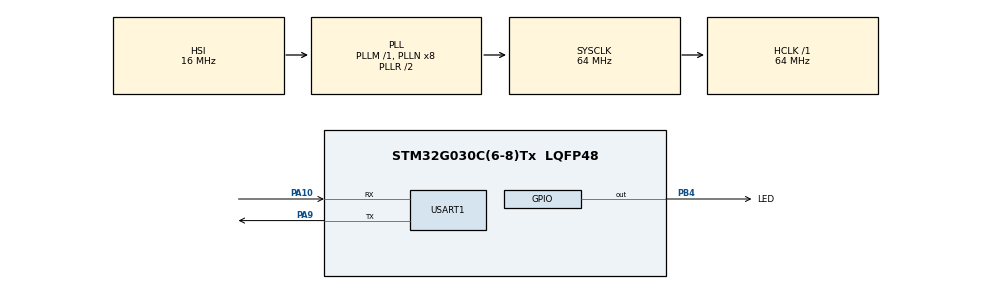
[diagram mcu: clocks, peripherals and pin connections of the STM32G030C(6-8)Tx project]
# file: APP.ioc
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Mcu.Family=STM32G0
Mcu.Name=STM32G030C(6-8)Tx
Mcu.Package=LQFP48
PA10.Mode=Asynchronous
PA10.Signal=USART1_RX
PA13.Mode=Serial_Wire
PA13.Signal=SYS_SWDIO
PA14-BOOT0.Mode=Serial_Wire
PA14-BOOT0.Signal=SYS_SWCLK
PA9.Mode=Asynchronous
PA9.Signal=USART1_TX
PB4.GPIO_Label=LED
PB4.Signal=GPIO_Output
ProjectManager.HeapSize=0x200
ProjectManager.StackSize=0x400
ProjectManager.TargetToolchain=MDK-ARM V5.32
RCC.ADCFreq_Value=64000000
RCC.AHBFreq_Value=64000000
RCC.CortexFreq_Value=64000000
RCC.EXTERNAL_CLOCK_VALUE=12288000
RCC.HCLKFreq_Value=64000000
RCC.HSE_VALUE=8000000
RCC.HSI_VALUE=16000000
RCC.LSE_VALUE=32768
RCC.SYSCLKFreq_VALUE=64000000
RCC.SYSCLKSource=RCC_SYSCLKSOURCE_PLLCLK
RCC.VCOOutputFreq_Value=128000000
USART1.VirtualMode-Asynchronous=VM_ASYNC
board=custom

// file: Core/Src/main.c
/* USER CODE BEGIN Header */
/**
  ******************************************************************************
  * @file           : main.c
  * @brief          : Main program body
  ******************************************************************************
  * @attention
  *
  * <h2><center>&copy; Copyright (c) 2021 STMicroelectronics.
  * All rights reserved.</center></h2>
  *
  * This software component is licensed by ST under BSD 3-Clause license,
  * the "License"; You may not use this file except in compliance with the
  * License. You may obtain a copy of the License at:
  *                        opensource.org/licenses/BSD-3-Clause
  *
  ******************************************************************************
  */
/* USER CODE END Header */
#include "main.h"

UART_HandleTypeDef huart1;

void SystemClock_Config(void);
static void MX_GPIO_Init(void);
static void MX_USART1_UART_Init(void);

int main(void)
{

  /* MCU Configuration--------------------------------------------------------*/

  /* Reset of all peripherals, Initializes the Flash interface and the Systick. */
  HAL_Init();

  /* Configure the system clock */
  SystemClock_Config();

  /* Initialize all configured peripherals */
  MX_GPIO_Init();
  MX_USART1_UART_Init();
  /* USER CODE BEGIN 2 */
    uint8_t buf[] = "\r\nSTM32G030 UART1(115200) APP V1.0\r\n";
    HAL_UART_Transmit(&huart1,buf,sizeof(buf)-1,100);
  /* USER CODE END 2 */

  /* Infinite loop */
  while (1)
  {

    /* USER CODE BEGIN 3 */
    HAL_Delay(500);
    HAL_GPIO_TogglePin(LED_GPIO_Port, LED_Pin);

  }
  /* USER CODE END 3 */
}

void SystemClock_Config(void)
{
  RCC_OscInitTypeDef RCC_OscInitStruct = {0};
  RCC_ClkInitTypeDef RCC_ClkInitStruct = {0};
  RCC_PeriphCLKInitTypeDef PeriphClkInit = {0};

  /** Configure the main internal regulator output voltage
  */
  HAL_PWREx_ControlVoltageScaling(PWR_REGULATOR_VOLTAGE_SCALE1);
  /** Initializes the RCC Oscillators according to the specified parameters
  * in the RCC_OscInitTypeDef structure.
  */
  RCC_OscInitStruct.OscillatorType = RCC_OSCILLATORTYPE_HSI;
  RCC_OscInitStruct.HSIState = RCC_HSI_ON;
  RCC_OscInitStruct.HSIDiv = RCC_HSI_DIV1;
  RCC_OscInitStruct.HSICalibrationValue = RCC_HSICALIBRATION_DEFAULT;
  RCC_OscInitStruct.PLL.PLLState = RCC_PLL_ON;
  RCC_OscInitStruct.PLL.PLLSource = RCC_PLLSOURCE_HSI;
  RCC_OscInitStruct.PLL.PLLM = RCC_PLLM_DIV1;
  RCC_OscInitStruct.PLL.PLLN = 8;
  RCC_OscInitStruct.PLL.PLLP = RCC_PLLP_DIV2;
  RCC_OscInitStruct.PLL.PLLR = RCC_PLLR_DIV2;
  if (HAL_RCC_OscConfig(&RCC_OscInitStruct) != HAL_OK)
  {
    Error_Handler();
  }
  /** Initializes the CPU, AHB and APB buses clocks
  */
  RCC_ClkInitStruct.ClockType = RCC_CLOCKTYPE_HCLK|RCC_CLOCKTYPE_SYSCLK
                              |RCC_CLOCKTYPE_PCLK1;
  RCC_ClkInitStruct.SYSCLKSource = RCC_SYSCLKSOURCE_PLLCLK;
  RCC_ClkInitStruct.AHBCLKDivider = RCC_SYSCLK_DIV1;
  RCC_ClkInitStruct.APB1CLKDivider = RCC_HCLK_DIV1;

  if (HAL_RCC_ClockConfig(&RCC_ClkInitStruct, FLASH_LATENCY_2) != HAL_OK)
  {
    Error_Handler();
  }
  /** Initializes the peripherals clocks
  */
  PeriphClkInit.PeriphClockSelection = RCC_PERIPHCLK_USART1;
  PeriphClkInit.Usart1ClockSelection = RCC_USART1CLKSOURCE_PCLK1;
  if (HAL_RCCEx_PeriphCLKConfig(&PeriphClkInit) != HAL_OK)
  {
    Error_Handler();
  }
}

static void MX_USART1_UART_Init(void)
{

  huart1.Instance = USART1;
  huart1.Init.BaudRate = 115200;
  huart1.Init.WordLength = UART_WORDLENGTH_8B;
  huart1.Init.StopBits = UART_STOPBITS_1;
  huart1.Init.Parity = UART_PARITY_NONE;
  huart1.Init.Mode = UART_MODE_TX_RX;
  huart1.Init.HwFlowCtl = UART_HWCONTROL_NONE;
  huart1.Init.OverSampling = UART_OVERSAMPLING_16;
  huart1.Init.OneBitSampling = UART_ONE_BIT_SAMPLE_DISABLE;
  huart1.Init.ClockPrescaler = UART_PRESCALER_DIV1;
  huart1.AdvancedInit.AdvFeatureInit = UART_ADVFEATURE_NO_INIT;
  if (HAL_UART_Init(&huart1) != HAL_OK)
  {
    Error_Handler();
  }
  if (HAL_UARTEx_SetTxFifoThreshold(&huart1, UART_TXFIFO_THRESHOLD_1_8) != HAL_OK)
  {
    Error_Handler();
  }
  if (HAL_UARTEx_SetRxFifoThreshold(&huart1, UART_RXFIFO_THRESHOLD_1_8) != HAL_OK)
  {
    Error_Handler();
  }
  if (HAL_UARTEx_DisableFifoMode(&huart1) != HAL_OK)
  {
    Error_Handler();
  }

}

static void MX_GPIO_Init(void)
{
  GPIO_InitTypeDef GPIO_InitStruct = {0};

  /* GPIO Ports Clock Enable */
  __HAL_RCC_GPIOA_CLK_ENABLE();
  __HAL_RCC_GPIOB_CLK_ENABLE();

  /*Configure GPIO pin Output Level */
  HAL_GPIO_WritePin(LED_GPIO_Port, LED_Pin, GPIO_PIN_RESET);

  /*Configure GPIO pin : LED_Pin */
  GPIO_InitStruct.Pin = LED_Pin;
  GPIO_InitStruct.Mode = GPIO_MODE_OUTPUT_PP;
  GPIO_InitStruct.Pull = GPIO_NOPULL;
  GPIO_InitStruct.Speed = GPIO_SPEED_FREQ_LOW;
  HAL_GPIO_Init(LED_GPIO_Port, &GPIO_InitStruct);

}

void Error_Handler(void)
{
  __disable_irq();
  while (1)
  {
  }
}

/************************ (C) COPYRIGHT STMicroelectronics *****END OF FILE****/
